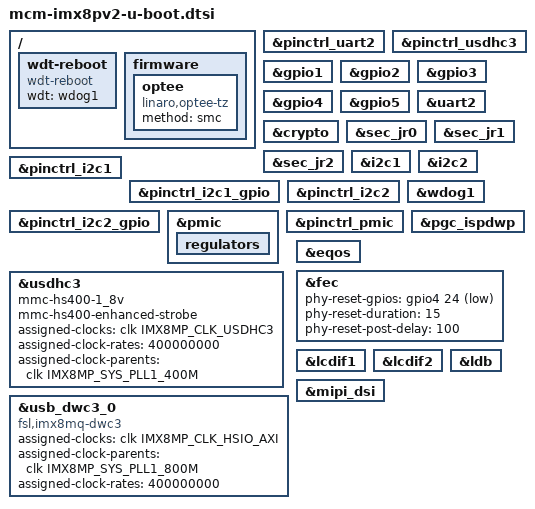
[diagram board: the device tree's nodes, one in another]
// SPDX-License-Identifier: GPL-2.0+
/*
 * Copyright 2026 CompuLab
 */

#include "imx8mp-u-boot.dtsi"
#include "compulab-imx8mp-binman.dtsi"

/ {
	wdt-reboot {
		compatible = "wdt-reboot";
		wdt = <&wdog1>;
		u-boot,dm-spl;
	};

	firmware {
		optee {
			compatible = "linaro,optee-tz";
			method = "smc";
		};
	};
};

&pinctrl_uart2 {
	u-boot,dm-spl;
};

&pinctrl_usdhc3 {
	u-boot,dm-spl;
};

&gpio1 {
	u-boot,dm-spl;
};

&gpio2 {
	u-boot,dm-spl;
};

&gpio3 {
	u-boot,dm-spl;
};

&gpio4 {
	u-boot,dm-spl;
};

&gpio5 {
	u-boot,dm-spl;
};

&uart2 {
	u-boot,dm-spl;
};

&crypto {
	u-boot,dm-spl;
};

&sec_jr0 {
	u-boot,dm-spl;
};

&sec_jr1 {
	u-boot,dm-spl;
};

&sec_jr2 {
	u-boot,dm-spl;
};

&i2c1 {
	u-boot,dm-spl;
};

&i2c2 {
	u-boot,dm-spl;
};

&pinctrl_i2c1 {
	u-boot,dm-spl;
};

&pinctrl_i2c1_gpio {
	u-boot,dm-spl;
};

&pinctrl_i2c2 {
	u-boot,dm-spl;
};

&pinctrl_i2c2_gpio {
	u-boot,dm-spl;
};

&wdog1 {
	u-boot,dm-spl;
};

&pmic {
	u-boot,dm-spl;
};

&pinctrl_pmic {
	u-boot,dm-spl;
};

&pmic {
	regulators {
		u-boot,dm-spl;
	};
};

&usdhc3 {
	u-boot,dm-spl;
	mmc-hs400-1_8v;
	mmc-hs400-enhanced-strobe;
	assigned-clocks = <&clk IMX8MP_CLK_USDHC3>;
	assigned-clock-rates = <400000000>;
	assigned-clock-parents = <&clk IMX8MP_SYS_PLL1_400M>;
};

&pgc_ispdwp {
	/delete-property/ clocks;
};

&usb_dwc3_0 {
	compatible = "fsl,imx8mq-dwc3", "snps,dwc3";
	assigned-clocks = <&clk IMX8MP_CLK_HSIO_AXI>;
	assigned-clock-parents = <&clk IMX8MP_SYS_PLL1_800M>;
	assigned-clock-rates = <400000000>;
};

/* Clock parents are configured by the U-Boot display/EQOS drivers. */
&eqos {
	/delete-property/ assigned-clocks;
	/delete-property/ assigned-clock-parents;
	/delete-property/ assigned-clock-rates;
};

/* This FEC driver reads reset properties from the MAC node. */
&fec {
	phy-reset-gpios = <&gpio4 24 GPIO_ACTIVE_LOW>;
	phy-reset-duration = <15>;
	phy-reset-post-delay = <100>;
};

&lcdif1 {
	/delete-property/ assigned-clocks;
	/delete-property/ assigned-clock-parents;
	/delete-property/ assigned-clock-rates;
};

&lcdif2 {
	/delete-property/ assigned-clocks;
	/delete-property/ assigned-clock-parents;
	/delete-property/ assigned-clock-rates;
};

&ldb {
	/delete-property/ assigned-clocks;
	/delete-property/ assigned-clock-parents;
	/delete-property/ assigned-clock-rates;
};

&mipi_dsi {
	/delete-property/ assigned-clocks;
	/delete-property/ assigned-clock-parents;
	/delete-property/ assigned-clock-rates;
};
